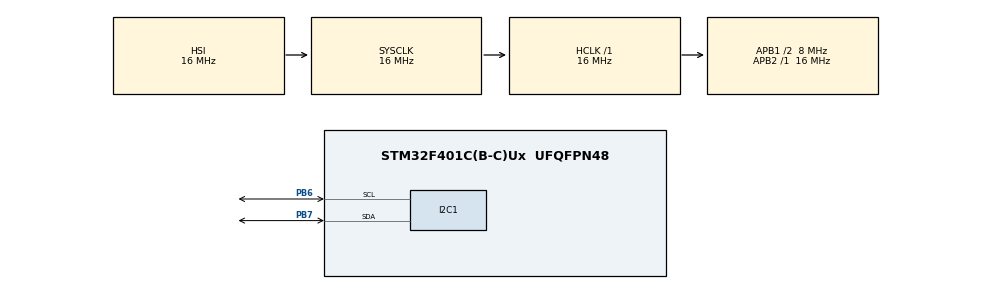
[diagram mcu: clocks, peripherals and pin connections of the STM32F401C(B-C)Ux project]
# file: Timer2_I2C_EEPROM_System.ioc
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Mcu.Family=STM32F4
Mcu.Name=STM32F401C(B-C)Ux
Mcu.Package=UFQFPN48
NVIC.PriorityGroup=NVIC_PRIORITYGROUP_4
NVIC.TIM2_IRQn=true\:0\:0\:false\:false\:true\:true\:true\:true
PB6.Mode=I2C
PB6.Signal=I2C1_SCL
PB7.Mode=I2C
PB7.Signal=I2C1_SDA
ProjectManager.HeapSize=0x200
ProjectManager.StackSize=0x400
ProjectManager.TargetToolchain=STM32CubeIDE
RCC.AHBFreq_Value=16000000
RCC.APB1CLKDivider=RCC_HCLK_DIV2
RCC.APB1Freq_Value=8000000
RCC.APB1TimFreq_Value=16000000
RCC.APB2Freq_Value=16000000
RCC.CortexFreq_Value=16000000
RCC.HSE_VALUE=25000000
RCC.HSI_VALUE=16000000
RCC.LSE_VALUE=32768
RCC.SYSCLKFreq_VALUE=16000000
RCC.VCOOutputFreq_Value=192000000
TIM2.Period=10000000
TIM2.Prescaler=8-1
VP_TIM2_VS_ClockSourceINT.Mode=Internal
board=custom

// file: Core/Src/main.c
/* USER CODE BEGIN Header */
/**
 ******************************************************************************
 * @file           : main.c
 * @brief          : Main program body
 ******************************************************************************
 * @attention
 *
 * Copyright (c) 2023 STMicroelectronics.
 * All rights reserved.
 *
 * This software is licensed under terms that can be found in the LICENSE file
 * in the root directory of this software component.
 * If no LICENSE file comes with this software, it is provided AS-IS.
 *
 ******************************************************************************
 */
/* USER CODE END Header */
#include "main.h"

/* USER CODE BEGIN Includes */
#include "EEPROM.h"
/* USER CODE END Includes */

/* USER CODE BEGIN PD */
#define PAGE_NUM_TIM_LOC        1
#define PAGE_NUM_FLAG_LOC       2

#define OFFSET_NUM_TIM          1
#define OFFSET_NUM_FLAG         3

#define TIM_SIZE_DATA           4
#define FLAG_SIZE_DATA          1

#define FIRST_TIME             0xFF
/* USER CODE END PD */

I2C_HandleTypeDef hi2c1;

TIM_HandleTypeDef htim2;

/* USER CODE BEGIN PV */
uint32_t g_timeElapsedSec = 0;
uint8_t g_buffer[4] = {0} ;
uint8_t *g_p2buffer = (uint8_t *)&g_timeElapsedSec;
uint8_t g_flag ;
uint8_t Done = 0x2;
/* USER CODE END PV */

void SystemClock_Config(void);
static void MX_GPIO_Init(void);
static void MX_I2C1_Init(void);
static void MX_TIM2_Init(void);

int main(void)
{

	/* MCU Configuration--------------------------------------------------------*/

	/* Reset of all peripherals, Initializes the Flash interface and the Systick. */
	HAL_Init();

	/* Configure the system clock */
	SystemClock_Config();

	/* Initialize all configured peripherals */
	MX_GPIO_Init();
	MX_I2C1_Init();
	MX_TIM2_Init();
	/* USER CODE BEGIN 2 */
	HAL_I2C_Init(&hi2c1);

	EEPROM_voidGetStoredTime();

	HAL_TIM_Base_Start_IT(&htim2);

	/* USER CODE END 2 */

	/* Infinite loop */
	while (1)
	{

	}
}

void SystemClock_Config(void)
{
	RCC_OscInitTypeDef RCC_OscInitStruct = {0};
	RCC_ClkInitTypeDef RCC_ClkInitStruct = {0};

	/** Configure the main internal regulator output voltage
	 */
	__HAL_RCC_PWR_CLK_ENABLE();
	__HAL_PWR_VOLTAGESCALING_CONFIG(PWR_REGULATOR_VOLTAGE_SCALE2);

	/** Initializes the RCC Oscillators according to the specified parameters
	 * in the RCC_OscInitTypeDef structure.
	 */
	RCC_OscInitStruct.OscillatorType = RCC_OSCILLATORTYPE_HSI;
	RCC_OscInitStruct.HSIState = RCC_HSI_ON;
	RCC_OscInitStruct.HSICalibrationValue = RCC_HSICALIBRATION_DEFAULT;
	RCC_OscInitStruct.PLL.PLLState = RCC_PLL_NONE;
	if (HAL_RCC_OscConfig(&RCC_OscInitStruct) != HAL_OK)
	{
		Error_Handler();
	}

	/** Initializes the CPU, AHB and APB buses clocks
	 */
	RCC_ClkInitStruct.ClockType = RCC_CLOCKTYPE_HCLK|RCC_CLOCKTYPE_SYSCLK
			|RCC_CLOCKTYPE_PCLK1|RCC_CLOCKTYPE_PCLK2;
	RCC_ClkInitStruct.SYSCLKSource = RCC_SYSCLKSOURCE_HSI;
	RCC_ClkInitStruct.AHBCLKDivider = RCC_SYSCLK_DIV1;
	RCC_ClkInitStruct.APB1CLKDivider = RCC_HCLK_DIV2;
	RCC_ClkInitStruct.APB2CLKDivider = RCC_HCLK_DIV1;

	if (HAL_RCC_ClockConfig(&RCC_ClkInitStruct, FLASH_LATENCY_0) != HAL_OK)
	{
		Error_Handler();
	}
}

static void MX_I2C1_Init(void)
{

	hi2c1.Instance = I2C1;
	hi2c1.Init.ClockSpeed = 100000;
	hi2c1.Init.DutyCycle = I2C_DUTYCYCLE_2;
	hi2c1.Init.OwnAddress1 = 0;
	hi2c1.Init.AddressingMode = I2C_ADDRESSINGMODE_7BIT;
	hi2c1.Init.DualAddressMode = I2C_DUALADDRESS_DISABLE;
	hi2c1.Init.OwnAddress2 = 0;
	hi2c1.Init.GeneralCallMode = I2C_GENERALCALL_DISABLE;
	hi2c1.Init.NoStretchMode = I2C_NOSTRETCH_DISABLE;
	if (HAL_I2C_Init(&hi2c1) != HAL_OK)
	{
		Error_Handler();
	}

}

static void MX_TIM2_Init(void)
{

	TIM_ClockConfigTypeDef sClockSourceConfig = {0};
	TIM_MasterConfigTypeDef sMasterConfig = {0};

	htim2.Instance = TIM2;
	htim2.Init.Prescaler = 8-1;
	htim2.Init.CounterMode = TIM_COUNTERMODE_UP;
	htim2.Init.Period = 10000000;
	htim2.Init.ClockDivision = TIM_CLOCKDIVISION_DIV1;
	htim2.Init.AutoReloadPreload = TIM_AUTORELOAD_PRELOAD_DISABLE;
	if (HAL_TIM_Base_Init(&htim2) != HAL_OK)
	{
		Error_Handler();
	}
	sClockSourceConfig.ClockSource = TIM_CLOCKSOURCE_INTERNAL;
	if (HAL_TIM_ConfigClockSource(&htim2, &sClockSourceConfig) != HAL_OK)
	{
		Error_Handler();
	}
	sMasterConfig.MasterOutputTrigger = TIM_TRGO_RESET;
	sMasterConfig.MasterSlaveMode = TIM_MASTERSLAVEMODE_DISABLE;
	if (HAL_TIMEx_MasterConfigSynchronization(&htim2, &sMasterConfig) != HAL_OK)
	{
		Error_Handler();
	}

}

static void MX_GPIO_Init(void)
{

	/* GPIO Ports Clock Enable */
	__HAL_RCC_GPIOB_CLK_ENABLE();

}

/* USER CODE BEGIN 4 */
uint32_t GetElapsedTime(void){
	uint32_t ElapsedTime = 0 ;
	EEPROM_Read(PAGE_NUM_TIM_LOC, OFFSET_NUM_TIM, (uint8_t *)&ElapsedTime, TIM_SIZE_DATA);
	return ElapsedTime;
}
/* Read Flag value */
void EEPROM_voidGetStoredTime(void){
	EEPROM_Read(PAGE_NUM_FLAG_LOC, OFFSET_NUM_FLAG, &g_flag, FLAG_SIZE_DATA);

	if(g_flag != FIRST_TIME){

		EEPROM_Read(PAGE_NUM_TIM_LOC, OFFSET_NUM_TIM, (uint8_t *)&g_timeElapsedSec, TIM_SIZE_DATA);
	}
	else{
		/* It's First time */
		/* Erase our used loc in EEPROM to make sure that is clear */
		for(uint8_t i = 0 ; i < 7 ; i++){
			EEPROM_PageErase(i);
		}
		EEPROM_Write(PAGE_NUM_FLAG_LOC, OFFSET_NUM_FLAG,&Done, FLAG_SIZE_DATA);
	}
}
void HAL_TIM_PeriodElapsedCallback(TIM_HandleTypeDef *htim){
	if(htim == &htim2){
		//Write Code here
		g_timeElapsedSec += 10;
		EEPROM_Write(PAGE_NUM_TIM_LOC, OFFSET_NUM_TIM,(uint8_t *)&g_timeElapsedSec,TIM_SIZE_DATA);
	}
}
/* USER CODE END 4 */

void Error_Handler(void)
{
	__disable_irq();
	while (1)
	{
	}
}
